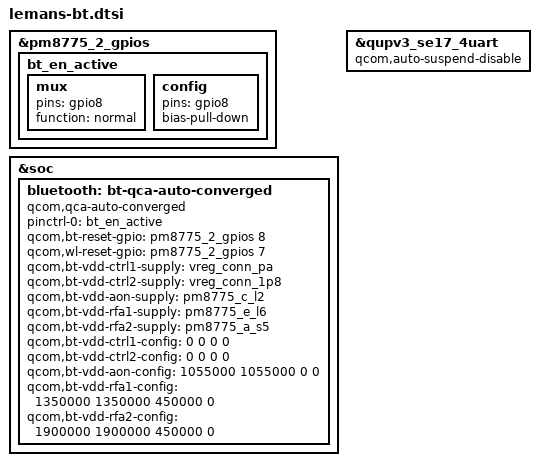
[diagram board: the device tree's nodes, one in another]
#include <dt-bindings/interconnect/qcom,lemans.h>

&pm8775_2_gpios {
	bt_en_active: bt_en_active {
		mux {
			pins = "gpio8";
			function = "normal";
		};

		config {
			pins = "gpio8";
			bias-pull-down;
		};
	};
};

&soc {
	bluetooth: bt-qca-auto-converged {
		compatible = "qcom,qca-auto-converged";
		pinctrl-names = "default";
		pinctrl-0 = <&bt_en_active>;
		/* BT_EN */
		qcom,bt-reset-gpio = <&pm8775_2_gpios 8 0>;
		/* WL_EN */
		qcom,wl-reset-gpio = <&pm8775_2_gpios 7 0>;
		/* PWR_CTR1_VDD_PA */
		qcom,bt-vdd-ctrl1-supply = <&vreg_conn_pa>;
		qcom,bt-vdd-ctrl2-supply = <&vreg_conn_1p8>;
		qcom,bt-vdd-aon-supply = <&pm8775_c_l2>;
		qcom,bt-vdd-rfa1-supply = <&pm8775_e_l6>;
		qcom,bt-vdd-rfa2-supply = <&pm8775_a_s5>;

		/* <vol_min, vol_max, load_curr, is_retention_supp> */
		qcom,bt-vdd-ctrl1-config = <0 0 0 0>;
		qcom,bt-vdd-ctrl2-config = <0 0 0 0>;
		qcom,bt-vdd-aon-config = <1055000 1055000 0 0>;
		qcom,bt-vdd-rfa1-config = <1350000 1350000 450000 0>;
		qcom,bt-vdd-rfa2-config = <1900000 1900000 450000 0>;
	};
};

&qupv3_se17_4uart {
	status = "ok";
	qcom,auto-suspend-disable;
};
